# R7FA0E303 register map
Vendor: Renesas Electronics Corporation; Series: RA0; File version: 1.00.00
CPU: CM23 r1p0, little endian, no MPU, no FPU, VTOR, 2 interrupt priority bits, 64 interrupts
Registers are 16-bit, read-write, reset 0x0 unless marked. A register's access mark holds for its fields unless they carry their own. Offsets are from the block's base; [hi:lo] are bit positions; {n}, {i} and the like mark numbered series; <NAME> marks a mode.

## SYSC — System Control
Base 0x4001E000
0x805 LIOTRM 8-bit reset 0x80 — Low-speed On-chip Oscillator Trimming Register
  [7:0] LIOTRM — LOCO User Trimming
0x808 HOCOCR 8-bit — High-speed On-chip Oscillator Control Register
  [0] HCSTP — HOCO Stop
    0=Operate the HOCO clock; 1=Stop the HOCO clock
0x80A LOCOCR 8-bit reset 0x1 — Low-speed On-chip Oscillator Control Register
  [0] LCSTP — LOCO Stop
    0=Operate the LOCO clock; 1=Stop the LOCO clock
0x812 OSCSF 8-bit ro reset 0x1 — Oscillation Stabilization Flag Register
  [0] HOCOSF — HOCO Clock Oscillation Stabilization Flag
    0=The HOCO clock is stopped, or the HOCO clock is being started and waiting for the precision of its oscillation to become stable is in progress; 1=The HOCO clock is operating with high precision
0x818 HOCODIV 8-bit reset 0x3 — High-speed On-chip Oscillator Frequency Select Register
  [2:0] DIV — High-speed On-chip Oscillator Clock Division Ratio
    0=× 1/1; 1=× 1/2; 2=× 1/4; 3=× 1/8; 4=× 1/16; 5=× 1/32; other=Others (Setting prohibited)
0x822 FSUBSCR 8-bit — FSUB Clock Source Control Register
  [0] CKSEL — FSUB Clock Source Select
    0=No clock source selected; 1=LOCO
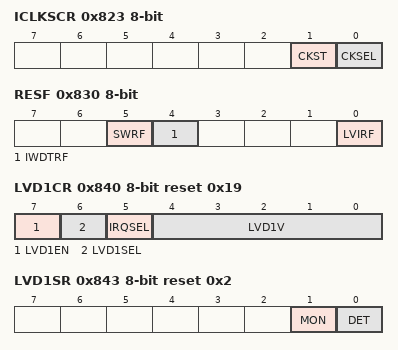
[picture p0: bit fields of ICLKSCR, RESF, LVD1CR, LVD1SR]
0x823 ICLKSCR 8-bit — ICLK Clock Source Control Register
  [1] CKST ro — ICLK Clock Source Status
    0=FMAIN; 1=FSUB
  [0] CKSEL — ICLK Clock Source Select
    0=FMAIN; 1=FSUB
0x824 OSMC 8-bit — Subsystem Clock Supply Mode Control Register
  [4] WUTMMCK0 — Selection of the Operating clock source for the 32-bit Interval Timer
    0=No clock source selected; 1=LOCO
0x830 RESF 8-bit ro (reset mask 0xCE) — Reset Status Flag Register
  [all] fields
    0=Internal reset request is not generated, or the RESF register is cleared; 1=Internal reset request is generated
  [5] SWRF — Internal Reset Request by Software Reset
  [4] IWDTRF — Internal Reset Request by Independent Watchdog Timer (IWDT)
  [0] LVIRF — Internal Reset Request by Voltage Detector (LVD0 or LVD1)
0x831 PORSR 8-bit — Power-On Reset Status Register
  [0] PORF — Checking Occurrence of Power-on Reset
    0=A value 1 has not been written, or a power-on reset has occurred; 1=No power-on reset has occurred
0x840 LVD1CR 8-bit reset 0x19 — Voltage Monitor 1 Circuit Control Register
  [7] LVD1EN — Enabling Operation of LVD1
    0=Operation stopped; 1=Operation enabled
  [6] LVD1SEL — Operation mode of LVD1
    0=Interrupt mode; 1=Reset mode
  [5] IRQSEL — Voltage Monitor 1 Interrupt Type Select
    0=Non-maskable interrupt; 1=Maskable interrupt
  [4:0] LVD1V — Voltage Detection 1 Level Select
    {v}=Vdet1_{v-14} (v=14..23); 24=Vdet1_A; 25=Vdet1_B; 26=Vdet1_C; 27=Vdet1_D; 28=Vdet1_E; 29=Vdet1_F; 30=Vdet1_10; 31=Vdet1_11; other=Others (Setting prohibited)
0x841 LVD1MKR 8-bit — Voltage Monitor 1 Circuit Mask Register
  [0] MK — Specification of Whether to Enable or Disable Rewriting th LVD1CR Register
    0=Rewriting of the LVD1CR register is disabled; 1=Rewriting of the LVD1CR register is enabled (reset and interrupt generation by LVD1 are masked)
0x843 LVD1SR 8-bit reset 0x2 — Voltage Monitor 1 Circuit Status Register
  [1] MON ro — Voltage Monitor 1 Signal Monitor Flag
    0=VCC < Vdet1; 1=VCC ≥ Vdet1 or MON is disabled
  [0] DET — Voltage Monitor 1 Voltage Variation Detection Flag
    0=Not detected; 1=Vdet1 crossing is detected
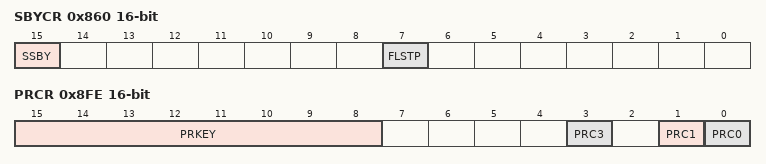
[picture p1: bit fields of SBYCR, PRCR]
0x860 SBYCR — Standby Control Register
  [15] SSBY — Software Standby Mode Select
    0=Sleep mode; 1=Software Standby mode
  [7] FLSTP — Flash Mode in Sleep Mode or in Snooze Mode
    0=Flash active; 1=Flash stop
0x863 SYOCDCR 8-bit — System Control OCD Control Register
  [7] DBGEN — Debugger Enable bit
    0=On-chip debugger is disabled; 1=On-chip debugger is enabled
0x8FE PRCR — Protect Register
  [15:8] PRKEY wo — PRC Key Code
  [3] PRC3 — Enable writing to the registers related to the LVD
    0=Disable writes; 1=Enable writes
  [1] PRC1 — Enable writing to the registers related to the low power modes
    0=Disable writes; 1=Enable writes
  [0] PRC0 — Enable writing to the registers related to the clock generation circuit
    0=Disable writes; 1=Enable writes
0xC02 MSTPCRA reset 0xFFBF — Module Stop Control Register A
  [6] MSTPA22 — DTC Module Stop
    0=Cancel the module-stop state; 1=Enter the module-stop state

## Notices in the file
This software is supplied by Renesas Electronics Corporation and is only intended for
use with Renesas products. No other uses are authorized. This software is owned by
Renesas Electronics Corporation and is protected under all applicable laws, including
copyright laws.
THIS SOFTWARE IS PROVIDED "AS IS" AND RENESAS MAKES NO WARRANTIES REGARDING
THIS SOFTWARE, WHETHER EXPRESS, IMPLIED OR STATUTORY, INCLUDING BUT NOT LIMITED TO
WARRANTIES OF MERCHANTABILITY, FITNESS FOR A PARTICULAR PURPOSE AND NON-INFRINGEMENT.
ALL SUCH WARRANTIES ARE EXPRESSLY DISCLAIMED. TO THE MAXIMUM EXTENT PERMITTED NOT
PROHIBITED BY LAW, NEITHER RENESAS ELECTRONICS CORPORATION NOR ANY OF ITS AFFILIATED
COMPANIES SHALL BE LIABLE FOR ANY DIRECT, INDIRECT, SPECIAL, INCIDENTAL OR CONSEQUENTIAL
DAMAGES FOR ANY REASON RELATED TO THIS SOFTWARE, EVEN IF RENESAS OR ITS AFFILIATES HAVE
BEEN ADVISED OF THE POSSIBILITY OF SUCH DAMAGES.
Renesas reserves the right, without notice, to make changes to this software and to
discontinue the availability of this software. By using this software, you agree to
the additional terms and conditions found by accessing the following link:
http://www.renesas.com/disclaimer
